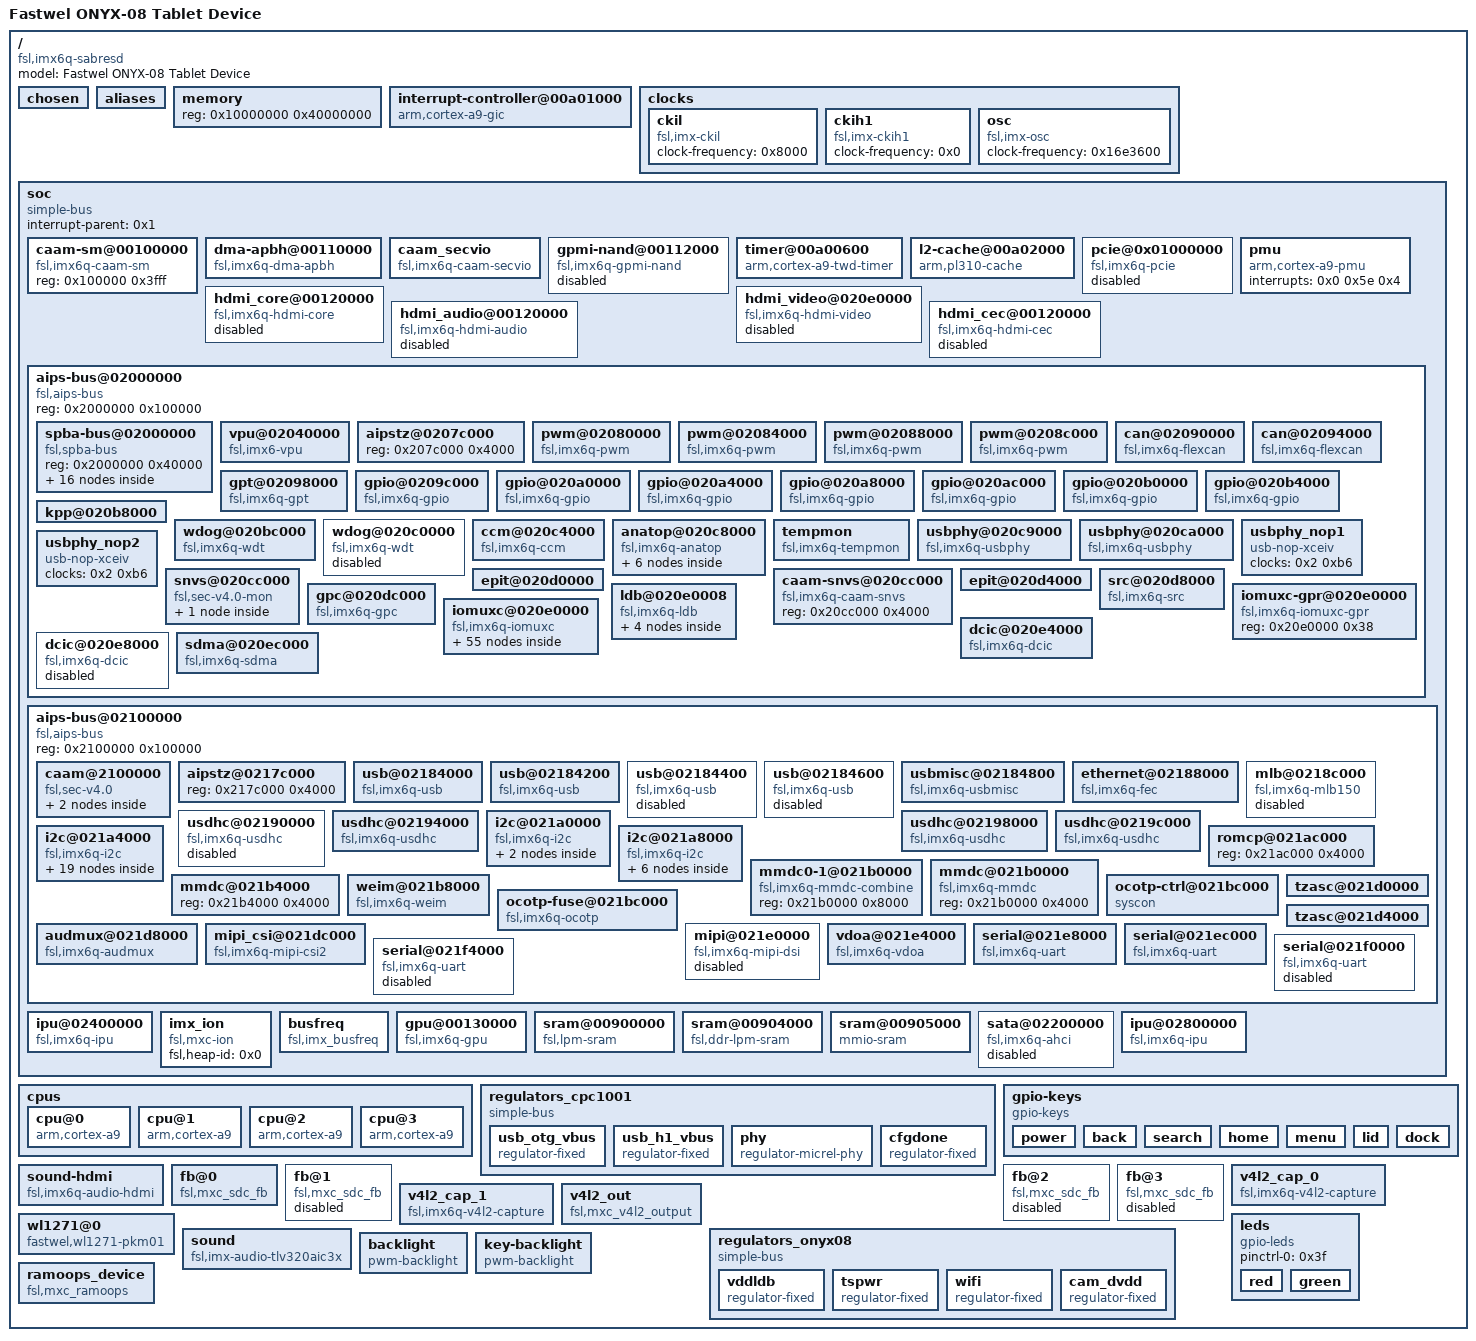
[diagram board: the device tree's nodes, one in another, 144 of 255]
/dts-v1/;

/ {
	#address-cells = <0x1>;
	#size-cells = <0x1>;
	model = "Fastwel ONYX-08 Tablet Device";
	compatible = "fsl,imx6q-sabresd", "fsl,imx6q", "fsl-onyx08";

	chosen {
	};

	aliases {
		gpio0 = "/soc/aips-bus@02000000/gpio@0209c000";
		gpio1 = "/soc/aips-bus@02000000/gpio@020a0000";
		gpio2 = "/soc/aips-bus@02000000/gpio@020a4000";
		gpio3 = "/soc/aips-bus@02000000/gpio@020a8000";
		gpio4 = "/soc/aips-bus@02000000/gpio@020ac000";
		gpio5 = "/soc/aips-bus@02000000/gpio@020b0000";
		gpio6 = "/soc/aips-bus@02000000/gpio@020b4000";
		i2c0 = "/soc/aips-bus@02100000/i2c@021a0000";
		i2c1 = "/soc/aips-bus@02100000/i2c@021a4000";
		i2c2 = "/soc/aips-bus@02100000/i2c@021a8000";
		ipu0 = "/soc/ipu@02400000";
		mmc0 = "/soc/aips-bus@02100000/usdhc@02190000";
		mmc1 = "/soc/aips-bus@02100000/usdhc@02194000";
		mmc2 = "/soc/aips-bus@02100000/usdhc@02198000";
		mmc3 = "/soc/aips-bus@02100000/usdhc@0219c000";
		serial0 = "/soc/aips-bus@02000000/spba-bus@02000000/serial@02020000";
		serial1 = "/soc/aips-bus@02100000/serial@021e8000";
		serial2 = "/soc/aips-bus@02100000/serial@021ec000";
		serial3 = "/soc/aips-bus@02100000/serial@021f0000";
		serial4 = "/soc/aips-bus@02100000/serial@021f4000";
		spi0 = "/soc/aips-bus@02000000/spba-bus@02000000/ecspi@02008000";
		spi1 = "/soc/aips-bus@02000000/spba-bus@02000000/ecspi@0200c000";
		spi2 = "/soc/aips-bus@02000000/spba-bus@02000000/ecspi@02010000";
		spi3 = "/soc/aips-bus@02000000/spba-bus@02000000/ecspi@02014000";
		usbphy0 = "/soc/aips-bus@02000000/usbphy@020c9000";
		usbphy1 = "/soc/aips-bus@02000000/usbphy@020ca000";
		ipu1 = "/soc/ipu@02800000";
		mxcfb0 = "/fb@0";
		mxcfb1 = "/fb@1";
		mxcfb2 = "/fb@2";
		mxcfb3 = "/fb@3";
	};

	memory {
		device_type = "memory";
		reg = <0x10000000 0x40000000>;
	};

	interrupt-controller@00a01000 {
		compatible = "arm,cortex-a9-gic";
		#interrupt-cells = <0x3>;
		#address-cells = <0x1>;
		#size-cells = <0x1>;
		interrupt-controller;
		reg = <0xa01000 0x1000 0xa00100 0x100>;
		linux,phandle = <0x1>;
		phandle = <0x1>;
	};

	clocks {
		#address-cells = <0x1>;
		#size-cells = <0x0>;

		ckil {
			compatible = "fsl,imx-ckil", "fixed-clock";
			clock-frequency = <0x8000>;
		};

		ckih1 {
			compatible = "fsl,imx-ckih1", "fixed-clock";
			clock-frequency = <0x0>;
		};

		osc {
			compatible = "fsl,imx-osc", "fixed-clock";
			clock-frequency = <0x16e3600>;
		};
	};

	soc {
		#address-cells = <0x1>;
		#size-cells = <0x1>;
		compatible = "simple-bus";
		interrupt-parent = <0x1>;
		ranges;

		caam-sm@00100000 {
			compatible = "fsl,imx6q-caam-sm";
			reg = <0x100000 0x3fff>;
		};

		dma-apbh@00110000 {
			compatible = "fsl,imx6q-dma-apbh", "fsl,imx28-dma-apbh";
			reg = <0x110000 0x2000>;
			interrupts = <0x0 0xd 0x4 0x0 0xd 0x4 0x0 0xd 0x4 0x0 0xd 0x4>;
			interrupt-names = "gpmi0", "gpmi1", "gpmi2", "gpmi3";
			#dma-cells = <0x1>;
			dma-channels = <0x4>;
			clocks = <0x2 0x6a>;
			linux,phandle = <0x3>;
			phandle = <0x3>;
		};

		caam_secvio {
			compatible = "fsl,imx6q-caam-secvio";
			interrupts = <0x0 0x14 0x4>;
			secvio_src = <0x8000001d>;
		};

		gpmi-nand@00112000 {
			compatible = "fsl,imx6q-gpmi-nand";
			#address-cells = <0x1>;
			#size-cells = <0x1>;
			reg = <0x112000 0x2000 0x114000 0x2000>;
			reg-names = "gpmi-nand", "bch";
			interrupts = <0x0 0xf 0x4>;
			interrupt-names = "bch";
			clocks = <0x2 0x98 0x2 0x99 0x2 0x97 0x2 0x96 0x2 0x95>;
			clock-names = "gpmi_io", "gpmi_apb", "gpmi_bch", "gpmi_bch_apb", "per1_bch";
			dmas = <0x3 0x0>;
			dma-names = "rx-tx";
			status = "disabled";
		};

		timer@00a00600 {
			compatible = "arm,cortex-a9-twd-timer";
			reg = <0xa00600 0x20>;
			interrupts = <0x1 0xd 0xf01>;
			clocks = <0x2 0xf>;
		};

		l2-cache@00a02000 {
			compatible = "arm,pl310-cache";
			reg = <0xa02000 0x1000>;
			interrupts = <0x0 0x5c 0x4>;
			cache-unified;
			cache-level = <0x2>;
			arm,tag-latency = <0x4 0x2 0x3>;
			arm,data-latency = <0x4 0x2 0x3>;
			linux,phandle = <0x36>;
			phandle = <0x36>;
		};

		pcie@0x01000000 {
			compatible = "fsl,imx6q-pcie", "snps,dw-pcie";
			reg = <0x1ffc000 0x4000 0x1f00000 0x80000>;
			reg-names = "dbi", "config";
			#address-cells = <0x3>;
			#size-cells = <0x2>;
			device_type = "pci";
			ranges = <0x81000000 0x0 0x0 0x1f80000 0x0 0x10000 0x82000000 0x0 0x1000000 0x1000000 0x0 0xf00000>;
			num-lanes = <0x1>;
			interrupts = <0x0 0x78 0x4>;
			interrupt-names = "msi";
			#interrupt-cells = <0x1>;
			interrupt-map-mask = <0x0 0x0 0x0 0x7>;
			interrupt-map = <0x0 0x0 0x0 0x1 0x1 0x0 0x7b 0x4 0x0 0x0 0x0 0x2 0x1 0x0 0x7a 0x4 0x0 0x0 0x0 0x3 0x1 0x0 0x79 0x4 0x0 0x0 0x0 0x4 0x1 0x0 0x78 0x4>;
			clocks = <0x2 0xbd 0x2 0xbb 0x2 0xce 0x2 0x90>;
			clock-names = "pcie_phy", "ref_100m", "pcie_bus", "pcie";
			status = "disabled";
			pinctrl-names = "default";
			pinctrl-0 = <0x4>;
			wake-up-gpio = <0x5 0xa 0x0>;
			reset-gpio = <0x6 0x13 0x0>;
		};

		pmu {
			compatible = "arm,cortex-a9-pmu";
			interrupts = <0x0 0x5e 0x4>;
		};

		hdmi_core@00120000 {
			compatible = "fsl,imx6q-hdmi-core";
			reg = <0x120000 0x9000>;
			clocks = <0x2 0x7c 0x2 0x7b 0x2 0x8a>;
			clock-names = "hdmi_isfr", "hdmi_iahb", "mipi_core";
			status = "disabled";
			ipu_id = <0x0>;
			disp_id = <0x1>;
		};

		hdmi_video@020e0000 {
			compatible = "fsl,imx6q-hdmi-video";
			reg = <0x20e0000 0x1000>;
			reg-names = "hdmi_gpr";
			interrupts = <0x0 0x73 0x4>;
			clocks = <0x2 0x7c 0x2 0x7b 0x2 0x8a>;
			clock-names = "hdmi_isfr", "hdmi_iahb", "mipi_core";
			status = "disabled";
			fsl,phy_reg_vlev = <0x294>;
			fsl,phy_reg_cksymtx = <0x800d>;
		};

		hdmi_audio@00120000 {
			compatible = "fsl,imx6q-hdmi-audio";
			clocks = <0x2 0x7c 0x2 0x7b 0x2 0x8a>;
			clock-names = "hdmi_isfr", "hdmi_iahb", "mipi_core";
			dmas = <0x7 0x2 0x18 0x0>;
			dma-names = "tx";
			status = "disabled";
			linux,phandle = <0x3d>;
			phandle = <0x3d>;
		};

		hdmi_cec@00120000 {
			compatible = "fsl,imx6q-hdmi-cec";
			interrupts = <0x0 0x73 0x4>;
			status = "disabled";
			pinctrl-names = "default";
			pinctrl-0 = <0x8>;
		};

		aips-bus@02000000 {
			compatible = "fsl,aips-bus", "simple-bus";
			#address-cells = <0x1>;
			#size-cells = <0x1>;
			reg = <0x2000000 0x100000>;
			ranges;

			spba-bus@02000000 {
				compatible = "fsl,spba-bus", "simple-bus";
				#address-cells = <0x1>;
				#size-cells = <0x1>;
				reg = <0x2000000 0x40000>;
				ranges;

				spdif@02004000 {
					compatible = "fsl,imx35-spdif";
					reg = <0x2004000 0x4000>;
					interrupts = <0x0 0x34 0x4>;
					dmas = <0x7 0xe 0x12 0x0 0x7 0xf 0x12 0x0>;
					dma-names = "rx", "tx";
					clocks = <0x2 0xf9 0x2 0x3 0x2 0xc5 0x2 0x6b 0x2 0x0 0x2 0x76 0x2 0x3e 0x2 0x8b 0x2 0x0 0x2 0x9c>;
					clock-names = "core", "rxtx0", "rxtx1", "rxtx2", "rxtx3", "rxtx4", "rxtx5", "rxtx6", "rxtx7", "dma";
					status = "disabled";
				};

				ecspi@02008000 {
					#address-cells = <0x1>;
					#size-cells = <0x0>;
					compatible = "fsl,imx6q-ecspi", "fsl,imx51-ecspi";
					reg = <0x2008000 0x4000>;
					interrupts = <0x0 0x1f 0x4>;
					clocks = <0x2 0x70 0x2 0x70>;
					clock-names = "ipg", "per";
					status = "okay";
					dmas = <0x7 0x3 0x7 0x1 0x7 0x4 0x7 0x2>;
					dma-names = "rx", "tx";
					fsl,spi-num-chipselects = <0x2>;
					cs-gpios = <0x6 0x1e 0x0 0x9 0x13 0x0>;
					pinctrl-names = "default";
					pinctrl-0 = <0xa>;

					at45db321d@0 {
						reg = <0x0>;
						#address-cells = <0x1>;
						#size-cells = <0x1>;
						compatible = "atmel,at45db321d", "atmel,at45", "atmel,dataflash";
						spi-max-frequency = <0x989680>;

						partition@0 {
							label = "U-Boot";
							reg = <0x0 0x40320>;
							read-only;
						};

						partition@40000 {
							label = "Kernel";
							reg = <0x40320 0x3dfce0>;
						};
					};
				};

				ecspi@0200c000 {
					#address-cells = <0x1>;
					#size-cells = <0x0>;
					compatible = "fsl,imx6q-ecspi", "fsl,imx51-ecspi";
					reg = <0x200c000 0x4000>;
					interrupts = <0x0 0x20 0x4>;
					clocks = <0x2 0x71 0x2 0x71>;
					clock-names = "ipg", "per";
					status = "disabled";
					dmas = <0x7 0x5 0x7 0x1 0x7 0x6 0x7 0x2>;
					dma-names = "rx", "tx";
					fsl,spi-num-chipselects = <0x2>;
					cs-gpios = <0x6 0x1a 0x0 0x6 0x1b 0x0>;
					pinctrl-names = "default";
					pinctrl-0 = <0xb>;
				};

				ecspi@02010000 {
					#address-cells = <0x1>;
					#size-cells = <0x0>;
					compatible = "fsl,imx6q-ecspi", "fsl,imx51-ecspi";
					reg = <0x2010000 0x4000>;
					interrupts = <0x0 0x21 0x4>;
					clocks = <0x2 0x72 0x2 0x72>;
					clock-names = "ipg", "per";
					status = "disabled";
					dmas = <0x7 0x7 0x7 0x1 0x7 0x8 0x7 0x2>;
					dma-names = "rx", "tx";
				};

				ecspi@02014000 {
					#address-cells = <0x1>;
					#size-cells = <0x0>;
					compatible = "fsl,imx6q-ecspi", "fsl,imx51-ecspi";
					reg = <0x2014000 0x4000>;
					interrupts = <0x0 0x22 0x4>;
					clocks = <0x2 0x73 0x2 0x73>;
					clock-names = "ipg", "per";
					status = "disabled";
					dmas = <0x7 0x9 0x7 0x1 0x7 0xa 0x7 0x2>;
					dma-names = "rx", "tx";
				};

				serial@02020000 {
					compatible = "fsl,imx6q-uart", "fsl,imx21-uart";
					reg = <0x2020000 0x4000>;
					interrupts = <0x0 0x1a 0x4>;
					clocks = <0x2 0xa0 0x2 0xa1>;
					clock-names = "ipg", "per";
					dmas = <0x7 0x19 0x4 0x0 0x7 0x1a 0x4 0x0>;
					dma-names = <0x747800>;
					status = "okay";
					pinctrl-names = "default";
					pinctrl-0 = <0xc>;
				};

				esai@02024000 {
					compatible = "fsl,imx35-esai";
					reg = <0x2024000 0x4000>;
					interrupts = <0x0 0x33 0x4>;
					clocks = <0x2 0xd9 0x2 0xd0 0x2 0x76 0x2 0xd9 0x2 0x9c>;
					clock-names = "core", "mem", "extal", "fsys", "dma";
					dmas = <0x7 0x17 0x15 0x0 0x7 0x18 0x15 0x0>;
					dma-names = "rx", "tx";
					status = "disabled";
				};

				ssi@02028000 {
					compatible = "fsl,imx6q-ssi", "fsl,imx21-ssi";
					reg = <0x2028000 0x4000>;
					interrupts = <0x0 0x2e 0x4>;
					clocks = <0x2 0xb2 0x2 0x9d>;
					clock-names = "ipg", "baud";
					dmas = <0x7 0x25 0x16 0x0 0x7 0x26 0x16 0x0>;
					dma-names = "rx", "tx";
					fsl,fifo-depth = <0xf>;
					fsl,ssi-dma-events = <0x26 0x25>;
					status = "disabled";
				};

				ssi@0202c000 {
					compatible = "fsl,imx6q-ssi", "fsl,imx21-ssi";
					reg = <0x202c000 0x4000>;
					interrupts = <0x0 0x2f 0x4>;
					clocks = <0x2 0xb3 0x2 0x9e>;
					clock-names = "ipg", "baud";
					dmas = <0x7 0x29 0x16 0x0 0x7 0x2a 0x16 0x0>;
					dma-names = "rx", "tx";
					fsl,fifo-depth = <0xf>;
					fsl,ssi-dma-events = <0x2a 0x29>;
					status = "okay";
					fsl,mode = "i2s-slave";
					linux,phandle = <0x40>;
					phandle = <0x40>;
				};

				ssi@02030000 {
					compatible = "fsl,imx6q-ssi", "fsl,imx21-ssi";
					reg = <0x2030000 0x4000>;
					interrupts = <0x0 0x30 0x4>;
					clocks = <0x2 0xb4 0x2 0x9f>;
					clock-names = "ipg", "baud";
					dmas = <0x7 0x2d 0x16 0x0 0x7 0x2e 0x16 0x0>;
					dma-names = "rx", "tx";
					fsl,fifo-depth = <0xf>;
					fsl,ssi-dma-events = <0x2e 0x2d>;
					status = "disabled";
				};

				asrc@02034000 {
					compatible = "fsl,imx53-asrc";
					reg = <0x2034000 0x4000>;
					interrupts = <0x0 0x32 0x4>;
					clocks = <0x2 0xda 0x2 0xdb 0x2 0x0 0x2 0x0 0x2 0x0 0x2 0x0 0x2 0x0 0x2 0x0 0x2 0x0 0x2 0x0 0x2 0x0 0x2 0x0 0x2 0x0 0x2 0x0 0x2 0x0 0x2 0x6b 0x2 0x0 0x2 0x0 0x2 0x9c>;
					clock-names = "mem", "ipg", "asrck_0", "asrck_1", "asrck_2", "asrck_3", "asrck_4", "asrck_5", "asrck_6", "asrck_7", "asrck_8", "asrck_9", "asrck_a", "asrck_b", "asrck_c", "asrck_d", "asrck_e", "asrck_f", "dma";
					dmas = <0x7 0x11 0x17 0x1 0x7 0x12 0x17 0x1 0x7 0x13 0x17 0x1 0x7 0x14 0x17 0x1 0x7 0x15 0x17 0x1 0x7 0x16 0x17 0x1>;
					dma-names = "rxa", "rxb", "rxc", "txa", "txb", "txc";
					fsl,asrc-rate = <0xbb80>;
					fsl,asrc-width = <0x10>;
					status = "okay";
				};

				spba@0203c000 {
					reg = <0x203c000 0x4000>;
				};

				ecspi@02018000 {
					#address-cells = <0x1>;
					#size-cells = <0x0>;
					compatible = "fsl,imx6q-ecspi", "fsl,imx51-ecspi";
					reg = <0x2018000 0x4000>;
					interrupts = <0x0 0x23 0x4>;
					clocks = <0x2 0x74 0x2 0x74>;
					clock-names = "ipg", "per";
					status = "disabled";
				};
			};

			vpu@02040000 {
				compatible = "fsl,imx6-vpu";
				reg = <0x2040000 0x3c000>;
				reg-names = "vpu_regs";
				interrupts = <0x0 0x3 0x1 0x0 0xc 0x4>;
				interrupt-names = "vpu_jpu_irq", "vpu_ipi_irq";
				clocks = <0x2 0xa8 0x2 0x8c 0x2 0x8e>;
				clock-names = "vpu_clk", "mmdc_ch0_axi", "ocram";
				iramsize = <0x21000>;
				iram = <0xd>;
				resets = <0xe 0x1>;
				power-domains = <0xf 0x1>;
				pu-supply = <0x10>;
			};

			aipstz@0207c000 {
				reg = <0x207c000 0x4000>;
			};

			pwm@02080000 {
				#pwm-cells = <0x2>;
				compatible = "fsl,imx6q-pwm", "fsl,imx27-pwm";
				reg = <0x2080000 0x4000>;
				interrupts = <0x0 0x53 0x4>;
				clocks = <0x2 0x3e 0x2 0x91>;
				clock-names = "ipg", "per";
				pinctrl-names = "default";
				pinctrl-0 = <0x11>;
				status = "okay";
				linux,phandle = <0x42>;
				phandle = <0x42>;
			};

			pwm@02084000 {
				#pwm-cells = <0x2>;
				compatible = "fsl,imx6q-pwm", "fsl,imx27-pwm";
				reg = <0x2084000 0x4000>;
				interrupts = <0x0 0x54 0x4>;
				clocks = <0x2 0x3e 0x2 0x92>;
				clock-names = "ipg", "per";
				pinctrl-names = "default";
				pinctrl-0 = <0x12>;
				status = "okay";
				linux,phandle = <0x43>;
				phandle = <0x43>;
			};

			pwm@02088000 {
				#pwm-cells = <0x2>;
				compatible = "fsl,imx6q-pwm", "fsl,imx27-pwm";
				reg = <0x2088000 0x4000>;
				interrupts = <0x0 0x55 0x4>;
				clocks = <0x2 0x3e 0x2 0x93>;
				clock-names = "ipg", "per";
			};

			pwm@0208c000 {
				#pwm-cells = <0x2>;
				compatible = "fsl,imx6q-pwm", "fsl,imx27-pwm";
				reg = <0x208c000 0x4000>;
				interrupts = <0x0 0x56 0x4>;
				clocks = <0x2 0x3e 0x2 0x94>;
				clock-names = "ipg", "per";
			};

			can@02090000 {
				compatible = "fsl,imx6q-flexcan";
				reg = <0x2090000 0x4000>;
				interrupts = <0x0 0x6e 0x4>;
				clocks = <0x2 0x6c 0x2 0x6d>;
				clock-names = "ipg", "per";
				stop-mode = <0x13 0x34 0x1c 0x10 0x11>;
				status = "okay";
				pinctrl-names = "default";
				pinctrl-0 = <0x14>;
				trx-nerr-gpio = <0x6 0x4 0x0>;
			};

			can@02094000 {
				compatible = "fsl,imx6q-flexcan";
				reg = <0x2094000 0x4000>;
				interrupts = <0x0 0x6f 0x4>;
				clocks = <0x2 0x6e 0x2 0x6f>;
				clock-names = "ipg", "per";
				stop-mode = <0x13 0x34 0x1d 0x10 0x12>;
				status = "okay";
				pinctrl-names = "default";
				pinctrl-0 = <0x15>;
				trx-nerr-gpio = <0x6 0x5 0x0>;
			};

			gpt@02098000 {
				compatible = "fsl,imx6q-gpt", "fsl,imx31-gpt";
				reg = <0x2098000 0x4000>;
				interrupts = <0x0 0x37 0x4>;
				clocks = <0x2 0x77 0x2 0x78>;
				clock-names = "ipg", "per";
			};

			gpio@0209c000 {
				compatible = "fsl,imx6q-gpio", "fsl,imx35-gpio";
				reg = <0x209c000 0x4000>;
				interrupts = <0x0 0x42 0x4 0x0 0x43 0x4>;
				gpio-controller;
				#gpio-cells = <0x2>;
				interrupt-controller;
				#interrupt-cells = <0x2>;
				linux,phandle = <0x28>;
				phandle = <0x28>;
			};

			gpio@020a0000 {
				compatible = "fsl,imx6q-gpio", "fsl,imx35-gpio";
				reg = <0x20a0000 0x4000>;
				interrupts = <0x0 0x44 0x4 0x0 0x45 0x4>;
				gpio-controller;
				#gpio-cells = <0x2>;
				interrupt-controller;
				#interrupt-cells = <0x2>;
				linux,phandle = <0x6>;
				phandle = <0x6>;
			};

			gpio@020a4000 {
				compatible = "fsl,imx6q-gpio", "fsl,imx35-gpio";
				reg = <0x20a4000 0x4000>;
				interrupts = <0x0 0x46 0x4 0x0 0x47 0x4>;
				gpio-controller;
				#gpio-cells = <0x2>;
				interrupt-controller;
				#interrupt-cells = <0x2>;
				linux,phandle = <0x9>;
				phandle = <0x9>;
			};

			gpio@020a8000 {
				compatible = "fsl,imx6q-gpio", "fsl,imx35-gpio";
				reg = <0x20a8000 0x4000>;
				interrupts = <0x0 0x48 0x4 0x0 0x49 0x4>;
				gpio-controller;
				#gpio-cells = <0x2>;
				interrupt-controller;
				#interrupt-cells = <0x2>;
				linux,phandle = <0x5>;
				phandle = <0x5>;
			};

			gpio@020ac000 {
				compatible = "fsl,imx6q-gpio", "fsl,imx35-gpio";
				reg = <0x20ac000 0x4000>;
				interrupts = <0x0 0x4a 0x4 0x0 0x4b 0x4>;
				gpio-controller;
				#gpio-cells = <0x2>;
				interrupt-controller;
				#interrupt-cells = <0x2>;
				linux,phandle = <0x3c>;
				phandle = <0x3c>;
			};

			gpio@020b0000 {
				compatible = "fsl,imx6q-gpio", "fsl,imx35-gpio";
				reg = <0x20b0000 0x4000>;
				interrupts = <0x0 0x4c 0x4 0x0 0x4d 0x4>;
				gpio-controller;
				#gpio-cells = <0x2>;
				interrupt-controller;
				#interrupt-cells = <0x2>;
				linux,phandle = <0x2d>;
				phandle = <0x2d>;
			};

			gpio@020b4000 {
				compatible = "fsl,imx6q-gpio", "fsl,imx35-gpio";
				reg = <0x20b4000 0x4000>;
				interrupts = <0x0 0x4e 0x4 0x0 0x4f 0x4>;
				gpio-controller;
				#gpio-cells = <0x2>;
				interrupt-controller;
				#interrupt-cells = <0x2>;
				linux,phandle = <0x32>;
				phandle = <0x32>;
			};

			kpp@020b8000 {
				reg = <0x20b8000 0x4000>;
				interrupts = <0x0 0x52 0x4>;
			};

			wdog@020bc000 {
				compatible = "fsl,imx6q-wdt", "fsl,imx21-wdt";
				reg = <0x20bc000 0x4000>;
				interrupts = <0x0 0x50 0x4>;
				clocks = <0x2 0x0>;
				status = "okay";
			};

			wdog@020c0000 {
				compatible = "fsl,imx6q-wdt", "fsl,imx21-wdt";
				reg = <0x20c0000 0x4000>;
				interrupts = <0x0 0x51 0x4>;
				clocks = <0x2 0x0>;
				status = "disabled";
			};

			ccm@020c4000 {
				compatible = "fsl,imx6q-ccm";
				reg = <0x20c4000 0x4000>;
				interrupts = <0x0 0x57 0x4 0x0 0x58 0x4>;
				#clock-cells = <0x1>;
				linux,phandle = <0x2>;
				phandle = <0x2>;
			};

			anatop@020c8000 {
				compatible = "fsl,imx6q-anatop", "syscon", "simple-bus";
				reg = <0x20c8000 0x1000>;
				interrupts = <0x0 0x31 0x4 0x0 0x36 0x4 0x0 0x7f 0x4>;
				linux,phandle = <0x16>;
				phandle = <0x16>;

				regulator-1p1@110 {
					compatible = "fsl,anatop-regulator";
					regulator-name = "vdd1p1";
					regulator-min-microvolt = <0xc3500>;
					regulator-max-microvolt = <0x14fb18>;
					regulator-always-on;
					anatop-reg-offset = <0x110>;
					anatop-vol-bit-shift = <0x8>;
					anatop-vol-bit-width = <0x5>;
					anatop-min-bit-val = <0x4>;
					anatop-min-voltage = <0xc3500>;
					anatop-max-voltage = <0x14fb18>;
					anatop-enable-bit = <0x0>;
				};

				regulator-3p0@120 {
					compatible = "fsl,anatop-regulator";
					regulator-name = "vdd3p0";
					regulator-min-microvolt = <0x280de8>;
					regulator-max-microvolt = <0x33e140>;
					anatop-reg-offset = <0x120>;
					anatop-vol-bit-shift = <0x8>;
					anatop-vol-bit-width = <0x5>;
					anatop-min-bit-val = <0x0>;
					anatop-min-voltage = <0x280de8>;
					anatop-max-voltage = <0x33e140>;
					anatop-enable-bit = <0x0>;
					linux,phandle = <0x18>;
					phandle = <0x18>;
				};

				regulator-2p5@130 {
					compatible = "fsl,anatop-regulator";
					regulator-name = "vdd2p5";
					regulator-min-microvolt = <0x1e8480>;
					regulator-max-microvolt = <0x29f630>;
					regulator-always-on;
					anatop-reg-offset = <0x130>;
					anatop-vol-bit-shift = <0x8>;
					anatop-vol-bit-width = <0x5>;
					anatop-min-bit-val = <0x0>;
					anatop-min-voltage = <0x1e8480>;
					anatop-max-voltage = <0x29f630>;
					anatop-enable-bit = <0x0>;
				};

				regulator-vddcore@140 {
					compatible = "fsl,anatop-regulator";
					regulator-name = "vddarm";
					regulator-min-microvolt = <0xb1008>;
					regulator-max-microvolt = <0x162010>;
					regulator-always-on;
					anatop-reg-offset = <0x140>;
					anatop-vol-bit-shift = <0x0>;
					anatop-vol-bit-width = <0x5>;
					anatop-delay-reg-offset = <0x170>;
					anatop-delay-bit-shift = <0x18>;
					anatop-delay-bit-width = <0x2>;
					anatop-min-bit-val = <0x1>;
					anatop-min-voltage = <0xb1008>;
					anatop-max-voltage = <0x162010>;
					regulator-allow-bypass;
					linux,phandle = <0x37>;
					phandle = <0x37>;
				};

				regulator-vddpu@140 {
					compatible = "fsl,anatop-regulator";
					regulator-name = "vddpu";
					regulator-min-microvolt = <0xb1008>;
					regulator-max-microvolt = <0x162010>;
					regulator-enable-ramp-delay = <0x96>;
					regulator-boot-on;
					anatop-reg-offset = <0x140>;
					anatop-vol-bit-shift = <0x9>;
					anatop-vol-bit-width = <0x5>;
					anatop-delay-reg-offset = <0x170>;
					anatop-delay-bit-shift = <0x1a>;
					anatop-delay-bit-width = <0x2>;
					anatop-min-bit-val = <0x1>;
					anatop-min-voltage = <0xb1008>;
					anatop-max-voltage = <0x162010>;
					regulator-allow-bypass;
					linux,phandle = <0x10>;
					phandle = <0x10>;
				};

				regulator-vddsoc@140 {
					compatible = "fsl,anatop-regulator";
					regulator-name = "vddsoc";
					regulator-min-microvolt = <0xb1008>;
					regulator-max-microvolt = <0x162010>;
					regulator-always-on;
					anatop-reg-offset = <0x140>;
					anatop-vol-bit-shift = <0x12>;
					anatop-vol-bit-width = <0x5>;
					anatop-delay-reg-offset = <0x170>;
					anatop-delay-bit-shift = <0x1c>;
					anatop-delay-bit-width = <0x2>;
					anatop-min-bit-val = <0x1>;
					anatop-min-voltage = <0xb1008>;
					anatop-max-voltage = <0x162010>;
					regulator-allow-bypass;
					linux,phandle = <0x38>;
					phandle = <0x38>;
				};
			};

			tempmon {
				compatible = "fsl,imx6q-tempmon";
				interrupts = <0x0 0x31 0x4>;
				fsl,tempmon = <0x16>;
				fsl,tempmon-data = <0x17>;
				clocks = <0x2 0xac>;
			};

			usbphy@020c9000 {
				compatible = "fsl,imx6q-usbphy", "fsl,imx23-usbphy";
				reg = <0x20c9000 0x1000>;
				interrupts = <0x0 0x2c 0x4>;
				clocks = <0x2 0xb6>;
				phy-3p0-supply = <0x18>;
				fsl,anatop = <0x16>;
				linux,phandle = <0x1c>;
				phandle = <0x1c>;
			};

			usbphy@020ca000 {
				compatible = "fsl,imx6q-usbphy", "fsl,imx23-usbphy";
				reg = <0x20ca000 0x1000>;
				interrupts = <0x0 0x2d 0x4>;
				clocks = <0x2 0xb7>;
				phy-3p0-supply = <0x18>;
				fsl,anatop = <0x16>;
				linux,phandle = <0x20>;
				phandle = <0x20>;
			};

			usbphy_nop1 {
				compatible = "usb-nop-xceiv";
				clocks = <0x2 0xb6>;
				clock-names = "main_clk";
				linux,phandle = <0x22>;
				phandle = <0x22>;
			};

			usbphy_nop2 {
				compatible = "usb-nop-xceiv";
				clocks = <0x2 0xb6>;
				clock-names = "main_clk";
				linux,phandle = <0x23>;
				phandle = <0x23>;
			};

			caam-snvs@020cc000 {
				compatible = "fsl,imx6q-caam-snvs";
				reg = <0x20cc000 0x4000>;
			};

			snvs@020cc000 {
				compatible = "fsl,sec-v4.0-mon", "simple-bus";
				#address-cells = <0x1>;
				#size-cells = <0x1>;
				ranges = <0x0 0x20cc000 0x4000>;

				snvs-rtc-lp@34 {
					compatible = "fsl,sec-v4.0-mon-rtc-lp";
					reg = <0x34 0x58>;
					interrupts = <0x0 0x13 0x4 0x0 0x14 0x4>;
				};
			};

			epit@020d0000 {
				reg = <0x20d0000 0x4000>;
				interrupts = <0x0 0x38 0x4>;
			};

			epit@020d4000 {
				reg = <0x20d4000 0x4000>;
				interrupts = <0x0 0x39 0x4>;
			};

			src@020d8000 {
				compatible = "fsl,imx6q-src", "fsl,imx51-src";
				reg = <0x20d8000 0x4000>;
				interrupts = <0x0 0x5b 0x4 0x0 0x60 0x4>;
				#reset-cells = <0x1>;
				linux,phandle = <0xe>;
				phandle = <0xe>;
			};

			gpc@020dc000 {
				compatible = "fsl,imx6q-gpc";
				reg = <0x20dc000 0x4000>;
				interrupts = <0x0 0x59 0x4 0x0 0x5a 0x4>;
				pu-supply = <0x10>;
				clocks = <0x2 0x7a 0x2 0x4a 0x2 0x79 0x2 0x1a 0x2 0x8f 0x2 0xa8 0x2 0x3e>;
				#power-domain-cells = <0x1>;
				fsl,cpu_pupscr_sw2iso = <0xf>;
				fsl,cpu_pupscr_sw = <0xf>;
				fsl,cpu_pdnscr_iso2sw = <0x1>;
				fsl,cpu_pdnscr_iso = <0x1>;
				fsl,ldo-bypass = <0x0>;
				fsl,wdog-reset = <0x1>;
				linux,phandle = <0xf>;
				phandle = <0xf>;
			};

			iomuxc-gpr@020e0000 {
				compatible = "fsl,imx6q-iomuxc-gpr", "syscon";
				reg = <0x20e0000 0x38>;
				linux,phandle = <0x13>;
				phandle = <0x13>;
			};

			iomuxc@020e0000 {
				compatible = "fsl,imx6q-iomuxc";
				reg = <0x20e0000 0x4000>;
				pinctrl-names = "default";
				pinctrl-0 = <0x19>;

				ipu2 {

					ipu2grp-1 {
						fsl,pins = <0x15c 0x470 0x0 0x1 0x0 0x10 0x160 0x474 0x0 0x1 0x0 0x10 0x164 0x478 0x0 0x1 0x0 0x10 0x168 0x47c 0x0 0x1 0x0 0x10 0x16c 0x480 0x0 0x1 0x0 0x80000000 0x170 0x484 0x0 0x1 0x0 0x10 0x174 0x488 0x0 0x1 0x0 0x10 0x178 0x48c 0x0 0x1 0x0 0x10 0x17c 0x490 0x0 0x1 0x0 0x10 0x180 0x494 0x0 0x1 0x0 0x10 0x184 0x498 0x0 0x1 0x0 0x10 0x188 0x49c 0x0 0x1 0x0 0x10 0x18c 0x4a0 0x0 0x1 0x0 0x10 0x190 0x4a4 0x0 0x1 0x0 0x10 0x194 0x4a8 0x0 0x1 0x0 0x10 0x198 0x4ac 0x0 0x1 0x0 0x10 0x19c 0x4b0 0x0 0x1 0x0 0x10 0x1a0 0x4b4 0x0 0x1 0x0 0x10 0x1a4 0x4b8 0x0 0x1 0x0 0x10 0x1a8 0x4bc 0x0 0x1 0x0 0x10 0x1ac 0x4c0 0x0 0x1 0x0 0x10 0x1b0 0x4c4 0x0 0x1 0x0 0x10 0x1b4 0x4c8 0x0 0x1 0x0 0x10 0x1b8 0x4cc 0x0 0x1 0x0 0x10 0x1bc 0x4d0 0x0 0x1 0x0 0x10 0x1c0 0x4d4 0x0 0x1 0x0 0x10 0x1c4 0x4d8 0x0 0x1 0x0 0x10 0x1c8 0x4dc 0x0 0x1 0x0 0x10 0x1cc 0x4e0 0x0 0x1 0x0 0x10>;
					};
				};

				pkmfec {

					pkmfec-1 {
						fsl,pins = <0x1d0 0x4e4 0x840 0x1 0x0 0x1b0b0 0x1f4 0x508 0x0 0x1 0x0 0x1b0b0 0x58 0x36c 0x0 0x1 0x0 0x1b0b0 0x5c 0x370 0x0 0x1 0x0 0x1b030 0x60 0x374 0x0 0x1 0x0 0x1b030 0x64 0x378 0x0 0x1 0x0 0x1b030 0x68 0x37c 0x0 0x1 0x0 0x1b030 0x74 0x388 0x0 0x1 0x0 0x1b0b0 0x1d4 0x4e8 0x0 0x1 0x0 0x1b0b0 0x84 0x398 0x844 0x1 0x0 0x1b0b0 0x6c 0x380 0x858 0x1 0x0 0x1b0b0>;
						linux,phandle = <0x24>;
						phandle = <0x24>;
					};

					pkmfec-1-sleep {
						fsl,pins = <0x1d0 0x4e4 0x840 0x1 0x0 0x1b0b0 0x1f4 0x508 0x0 0x1 0x0 0x1b0b0 0x58 0x36c 0x0 0x1 0x0 0x1b0b0 0x5c 0x370 0x0 0x1 0x0 0x1b030 0x60 0x374 0x0 0x1 0x0 0x1b030 0x64 0x378 0x0 0x1 0x0 0x1b030 0x68 0x37c 0x0 0x1 0x0 0x1b030 0x74 0x388 0x0 0x1 0x0 0x1b0b0 0x1d4 0x4e8 0x0 0x1 0x0 0x1b0b0 0x84 0x398 0x844 0x1 0x0 0x1b0b0 0x6c 0x380 0x858 0x1 0x0 0x1b0b0>;
						linux,phandle = <0x25>;
						phandle = <0x25>;
					};
				};

				reg_phy {

					phy_on {
						fsl,pins = <0x70 0x384 0x848 0x1 0x0 0x1b030 0x78 0x38c 0x84c 0x1 0x0 0x1b030 0x7c 0x390 0x850 0x1 0x0 0x1b030 0x80 0x394 0x854 0x1 0x0 0x1b030>;
						linux,phandle = <0x3a>;
						phandle = <0x3a>;
					};

					phy_off {
						fsl,pins = <0x70 0x384 0x0 0x5 0x0 0x1b030 0x78 0x38c 0x0 0x5 0x0 0x1b030 0x7c 0x390 0x0 0x5 0x0 0x1b030 0x80 0x394 0x0 0x5 0x0 0x1b030>;
						linux,phandle = <0x3b>;
						phandle = <0x3b>;
					};
				};

				uart1 {

					uart1grp-1 {
						fsl,pins = <0x280 0x650 0x0 0x3 0x0 0x1b0b1 0x284 0x654 0x920 0x3 0x1 0x1b0b1>;
						linux,phandle = <0xc>;
						phandle = <0xc>;
					};
				};

				uart2 {

					uart2grp-1 {
						fsl,pins = <0xbc 0x3d0 0x0 0x4 0x0 0x1b0b1 0xc0 0x3d4 0x928 0x4 0x1 0x1b0b1>;
					};

					uart2grp-3 {
						fsl,pins = <0xbc 0x3d0 0x0 0x4 0x0 0x1b0b1 0xc0 0x3d4 0x928 0x4 0x1 0x1b0b1 0xc4 0x3d8 0x0 0x4 0x0 0x1b0b1 0xc8 0x3dc 0x924 0x4 0x1 0x1b0b1>;
						linux,phandle = <0x34>;
						phandle = <0x34>;
					};
				};

				uart3 {

					uart3grp-1 {
						fsl,pins = <0xb4 0x3c8 0x0 0x2 0x0 0x1b0b1 0xb8 0x3cc 0x930 0x2 0x1 0x1b0b1>;
						linux,phandle = <0x35>;
						phandle = <0x35>;
					};
				};

				pwm1 {

					pwm1grp-1 {
						fsl,pins = <0x344 0x72c 0x0 0x3 0x0 0x1b0b1>;
						linux,phandle = <0x11>;
						phandle = <0x11>;
					};
				};

				pwm2 {

					pwm2grp-1 {
						fsl,pins = <0x34c 0x734 0x0 0x3 0x0 0x1b0b1>;
						linux,phandle = <0x12>;
						phandle = <0x12>;
					};
				};

				usbotg {

					usbotggrp-1 {
						fsl,pins = <0x224 0x5f4 0x4 0x3 0xff0d0101 0x17059>;
						linux,phandle = <0x1f>;
						phandle = <0x1f>;
					};
				};

				hdmi_cec {

					hdmicecgrp-2 {
						fsl,pins = <0x20c 0x5dc 0x88c 0x6 0x1 0x1f8b0>;
						linux,phandle = <0x8>;
						phandle = <0x8>;
					};
				};

				flexcan1 {

					flexcan1grp-2 {
						fsl,pins = <0x240 0x610 0x0 0x3 0x0 0x80000000 0x20c 0x5dc 0x7e4 0x2 0x0 0x80000000>;
					};
				};

				flexcan2 {

					flexcan2grp-1 {
						fsl,pins = <0x218 0x5e8 0x0 0x0 0x0 0x80000000 0x21c 0x5ec 0x7e8 0x0 0x0 0x80000000>;
						linux,phandle = <0x15>;
						phandle = <0x15>;
					};
				};

				i2c1 {

					i2c1grp-2 {
						fsl,pins = <0x278 0x648 0x89c 0x4 0x1 0x4001b8b1 0x27c 0x64c 0x898 0x4 0x1 0x4001b8b1>;
						linux,phandle = <0x2b>;
						phandle = <0x2b>;
					};
				};

				i2c2 {

					i2c2grp-2 {
						fsl,pins = <0x210 0x5e0 0x8a0 0x4 0x1 0x4001b8b1 0x214 0x5e4 0x8a4 0x4 0x1 0x4001b8b1>;
						linux,phandle = <0x2e>;
						phandle = <0x2e>;
					};
				};

				i2c3 {

					i2c3grp-2 {
						fsl,pins = <0x22c 0x5fc 0x8a8 0x2 0x1 0x4001b8b1 0x230 0x600 0x8ac 0x2 0x1 0x4001b8b1>;
						linux,phandle = <0x31>;
						phandle = <0x31>;
					};
				};

				usdhc2 {

					usdhc2grp-2-50MHz-40Ohm {
						fsl,pins = <0x358 0x740 0x0 0x0 0x0 0x17071 0x354 0x73c 0x0 0x0 0x0 0x10071 0x54 0x368 0x0 0x0 0x0 0x17071 0x4c 0x360 0x0 0x0 0x0 0x17071 0x50 0x364 0x0 0x0 0x0 0x17071 0x35c 0x744 0x0 0x0 0x0 0x17071>;
						linux,phandle = <0x27>;
						phandle = <0x27>;
					};
				};

				usdhc3 {

					usdhc3grp-2 {
						fsl,pins = <0x2b8 0x6a0 0x0 0x0 0x0 0x17059 0x2bc 0x6a4 0x0 0x0 0x0 0x10059 0x2c0 0x6a8 0x0 0x0 0x0 0x17059 0x2c4 0x6ac 0x0 0x0 0x0 0x17059 0x2c8 0x6b0 0x0 0x0 0x0 0x17059 0x2cc 0x6b4 0x0 0x0 0x0 0x17059>;
						linux,phandle = <0x29>;
						phandle = <0x29>;
					};
				};

				usdhc4 {

					usdhc4grp-1 {
						fsl,pins = <0x2d8 0x6c0 0x0 0x1 0x0 0x1b0b0 0x2f4 0x6dc 0x0 0x0 0x0 0x17059 0x2f8 0x6e0 0x0 0x0 0x0 0x10059 0x31c 0x704 0x0 0x1 0x0 0x17059 0x320 0x708 0x0 0x1 0x0 0x17059 0x324 0x70c 0x0 0x1 0x0 0x17059 0x328 0x710 0x0 0x1 0x0 0x17059 0x32c 0x714 0x0 0x1 0x0 0x17059 0x330 0x718 0x0 0x1 0x0 0x17059 0x334 0x71c 0x0 0x1 0x0 0x17059 0x338 0x720 0x0 0x1 0x0 0x17059>;
						linux,phandle = <0x2a>;
						phandle = <0x2a>;
					};
				};

				ecspi1 {

					ecspi1grp-1 {
						fsl,pins = <0x94 0x3a8 0x7f8 0x1 0x0 0x100b1 0x98 0x3ac 0x7fc 0x1 0x0 0x100b1 0x90 0x3a4 0x7f4 0x1 0x0 0x100b1>;
						linux,phandle = <0xa>;
						phandle = <0xa>;
					};
				};

				ecspi2 {

					ecspi2grp-1 {
						fsl,pins = <0xf8 0x40c 0x810 0x2 0x0 0x100b1 0xfc 0x410 0x818 0x2 0x0 0x100b1 0x100 0x414 0x814 0x2 0x0 0x100b1>;
						linux,phandle = <0xb>;
						phandle = <0xb>;
					};
				};

				onyx08_can1 {

					flexcan1grp-3 {
						fsl,pins = <0x240 0x610 0x0 0x3 0x0 0x1b0b0 0x244 0x614 0x7e4 0x3 0x1 0x1b0b0>;
						linux,phandle = <0x14>;
						phandle = <0x14>;
					};
				};

				pcie {

					pcie_grp {
						fsl,pins = <0xe8 0x3fc 0x0 0x5 0x0 0x1b0b0 0x208 0x5d8 0x0 0x5 0x0 0x1b0b0>;
						linux,phandle = <0x4>;
						phandle = <0x4>;
					};
				};

				leds {

					gpio_leds {
						fsl,pins = <0x1c4 0x4d8 0x0 0x5 0x0 0x1b0b1 0x1a8 0x4bc 0x0 0x5 0x0 0x1b0b1>;
						linux,phandle = <0x3f>;
						phandle = <0x3f>;
					};
				};

				audmux {

					audmux-2 {
						fsl,pins = <0x274 0x644 0x0 0x4 0x0 0x130b0 0x268 0x638 0x0 0x4 0x0 0x130b0 0x26c 0x63c 0x0 0x4 0x0 0x110b0 0x270 0x640 0x0 0x4 0x0 0x130b0>;
						linux,phandle = <0x33>;
						phandle = <0x33>;
					};
				};

				battery {

					bq40z60-pins {
						fsl,pins = <0x2d4 0x6bc 0x0 0x5 0x0 0x1f0b0 0x2ec 0x6d4 0x0 0x5 0x0 0x1f0b0 0x2f0 0x6d8 0x0 0x5 0x0 0x110b0>;
						linux,phandle = <0x2c>;
						phandle = <0x2c>;
					};
				};

				hog {

					hoggrp-1 {
						fsl,pins = <0x238 0x608 0x0 0x6 0x0 0x80000000 0x254 0x624 0x0 0x3 0x0 0x130b0 0x170 0x484 0x0 0x5 0x0 0x1f0b0 0xa0 0x3b4 0x0 0x5 0x0 0x1f0b0 0x178 0x48c 0x0 0x5 0x0 0x8b0 0x17c 0x490 0x0 0x5 0x0 0x8b0 0xcc 0x3e0 0x948 0x6 0x0 0x1b0b0 0xd0 0x3e4 0x0 0x6 0x0 0x1b0b0 0xa4 0x3b8 0x944 0x4 0x0 0x1b0b0 0xa8 0x3bc 0x0 0x4 0x0 0x1b0b0 0x2b0 0x698 0x0 0x5 0x0 0x1b0b0 0x2b4 0x69c 0x0 0x5 0x0 0x1b0b0 0x2ac 0x694 0x0 0x5 0x0 0x1b0b0 0x2a8 0x690 0x0 0x5 0x0 0x1b0b0 0x194 0x4a8 0x0 0x5 0x0 0x1b0b0 0xe4 0x3f8 0x0 0x5 0x0 0x1b0b0>;
						linux,phandle = <0x19>;
						phandle = <0x19>;
					};
				};
			};

			ldb@020e0008 {
				#address-cells = <0x1>;
				#size-cells = <0x0>;
				gpr = <0x13>;
				status = "okay";
				compatible = "fsl,imx6q-ldb", "fsl,imx53-ldb";
				clocks = <0x2 0x87 0x2 0x88 0x2 0x27 0x2 0x28 0x2 0x29 0x2 0x2a 0x2 0xb8 0x2 0xb9 0x2 0xd1 0x2 0xd2 0x2 0xd3 0x2 0xd4>;
				clock-names = "ldb_di0", "ldb_di1", "di0_sel", "di1_sel", "di2_sel", "di3_sel", "ldb_di0_div_3_5", "ldb_di1_div_3_5", "ldb_di0_div_7", "ldb_di1_div_7", "ldb_di0_div_sel", "ldb_di1_div_sel";

				lvds-channel@0 {
					reg = <0x0>;
					status = "okay";
					crtc = "ipu2-di0";
					vddldb-supply = <0x1a>;
					fsl,data-mapping = "spwg";
					fsl,data-width = <0x18>;
					primary;

					display-timings {
						native-mode = <0x1b>;

						G084SN05V9 {
							clock-frequency = <0x25f4cc0>;
							hactive = <0x320>;
							vactive = <0x258>;
							hback-porch = <0x80>;
							hfront-porch = <0x80>;
							vback-porch = <0xe>;
							vfront-porch = <0xe>;
							hsync-len = <0x1>;
							vsync-len = <0x1>;
							linux,phandle = <0x1b>;
							phandle = <0x1b>;
						};
					};
				};

				lvds-channel@1 {
					reg = <0x1>;
					status = "disabled";
					crtc = "ipu2-di1";
				};
			};

			dcic@020e4000 {
				compatible = "fsl,imx6q-dcic";
				reg = <0x20e4000 0x4000>;
				interrupts = <0x0 0x7c 0x4>;
				clocks = <0x2 0xd6 0x2 0xd6>;
				clock-names = "dcic", "disp-axi";
				gpr = <0x13>;
				status = "okay";
				dcic_id = <0x0>;
				dcic_mux = "dcic-hdmi";
			};

			dcic@020e8000 {
				compatible = "fsl,imx6q-dcic";
				reg = <0x20e8000 0x4000>;
				interrupts = <0x0 0x7d 0x4>;
				clocks = <0x2 0xd7 0x2 0xd7>;
				clock-names = "dcic", "disp-axi";
				gpr = <0x13>;
				status = "disabled";
			};

			sdma@020ec000 {
				compatible = "fsl,imx6q-sdma", "fsl,imx35-sdma";
				reg = <0x20ec000 0x4000>;
				interrupts = <0x0 0x2 0x4>;
				clocks = <0x2 0x9b 0x2 0x9b>;
				clock-names = "ipg", "ahb";
				#dma-cells = <0x3>;
				fsl,sdma-ram-script-name = "imx/sdma/sdma-imx6q.bin";
				linux,phandle = <0x7>;
				phandle = <0x7>;
			};
		};

		aips-bus@02100000 {
			compatible = "fsl,aips-bus", "simple-bus";
			#address-cells = <0x1>;
			#size-cells = <0x1>;
			reg = <0x2100000 0x100000>;
			ranges;

			caam@2100000 {
				compatible = "fsl,sec-v4.0";
				#address-cells = <0x1>;
				#size-cells = <0x1>;
				reg = <0x2100000 0x40000>;
				ranges = <0x0 0x2100000 0x40000>;
				interrupt-parent = <0x1>;
				clocks = <0x2 0xf6 0x2 0xf7 0x2 0xf8 0x2 0xc4>;
				clock-names = "caam_mem", "caam_aclk", "caam_ipg", "caam_emi_slow";

				jr0@1000 {
					compatible = "fsl,sec-v4.0-job-ring";
					reg = <0x1000 0x1000>;
					interrupt-parent = <0x1>;
					interrupts = <0x0 0x69 0x4>;
				};

				jr1@2000 {
					compatible = "fsl,sec-v4.0-job-ring";
					reg = <0x2000 0x1000>;
					interrupt-parent = <0x1>;
					interrupts = <0x0 0x6a 0x4>;
				};
			};

			aipstz@0217c000 {
				reg = <0x217c000 0x4000>;
			};

			usb@02184000 {
				compatible = "fsl,imx6q-usb", "fsl,imx27-usb";
				reg = <0x2184000 0x200>;
				interrupts = <0x0 0x2b 0x4>;
				clocks = <0x2 0xa2>;
				fsl,usbphy = <0x1c>;
				fsl,usbmisc = <0x1d 0x0>;
				fsl,anatop = <0x16>;
				status = "okay";
				vbus-supply = <0x1e>;
				pinctrl-names = "default";
				pinctrl-0 = <0x1f>;
				disable-over-current;
			};

			usb@02184200 {
				compatible = "fsl,imx6q-usb", "fsl,imx27-usb";
				reg = <0x2184200 0x200>;
				interrupts = <0x0 0x28 0x4>;
				clocks = <0x2 0xa2>;
				fsl,usbphy = <0x20>;
				fsl,usbmisc = <0x1d 0x1>;
				status = "okay";
				vbus-supply = <0x21>;
				dr_mode = "host";
			};

			usb@02184400 {
				compatible = "fsl,imx6q-usb", "fsl,imx27-usb";
				reg = <0x2184400 0x200>;
				interrupts = <0x0 0x29 0x4>;
				clocks = <0x2 0xa2>;
				fsl,usbmisc = <0x1d 0x2>;
				phy_type = "hsic";
				fsl,usbphy = <0x22>;
				fsl,anatop = <0x16>;
				status = "disabled";
			};

			usb@02184600 {
				compatible = "fsl,imx6q-usb", "fsl,imx27-usb";
				reg = <0x2184600 0x200>;
				interrupts = <0x0 0x2a 0x4>;
				clocks = <0x2 0xa2>;
				fsl,usbmisc = <0x1d 0x3>;
				phy_type = "hsic";
				fsl,usbphy = <0x23>;
				fsl,anatop = <0x16>;
				status = "disabled";
			};

			usbmisc@02184800 {
				#index-cells = <0x1>;
				compatible = "fsl,imx6q-usbmisc";
				reg = <0x2184800 0x200>;
				clocks = <0x2 0xa2>;
				linux,phandle = <0x1d>;
				phandle = <0x1d>;
			};

			ethernet@02188000 {
				compatible = "fsl,imx6q-fec";
				reg = <0x2188000 0x4000>;
				interrupts-extended = <0x1 0x0 0x76 0x4 0x1 0x0 0x77 0x4>;
				clocks = <0x2 0x75 0x2 0x75 0x2 0xbe>;
				clock-names = "ipg", "ahb", "ptp";
				status = "okay";
				pinctrl-0 = <0x24>;
				pinctrl-1 = <0x25>;
				pinctrl-names = "default", "sleep";
				phy-mode = "rgmii";
				max-speed = <0x3e8>;
				phy-supply = <0x26>;
			};

			mlb@0218c000 {
				compatible = "fsl,imx6q-mlb150";
				reg = <0x218c000 0x4000>;
				interrupts = <0x0 0x35 0x4 0x0 0x75 0x4 0x0 0x7e 0x4>;
				clocks = <0x2 0x8b 0x2 0xaf>;
				clock-names = "mlb", "pll8_mlb";
				iram = <0xd>;
				status = "disabled";
			};

			usdhc@02190000 {
				compatible = "fsl,imx6q-usdhc";
				reg = <0x2190000 0x4000>;
				interrupts = <0x0 0x16 0x4>;
				clocks = <0x2 0xa3 0x2 0xa3 0x2 0xa3>;
				clock-names = "ipg", "ahb", "per";
				bus-width = <0x4>;
				status = "disabled";
			};

			usdhc@02194000 {
				compatible = "fsl,imx6q-usdhc";
				reg = <0x2194000 0x4000>;
				interrupts = <0x0 0x17 0x4>;
				clocks = <0x2 0xa4 0x2 0xa4 0x2 0xa4>;
				clock-names = "ipg", "ahb", "per";
				bus-width = <0x4>;
				status = "okay";
				pinctrl-names = "default";
				pinctrl-0 = <0x27>;
				cd-gpios = <0x28 0x4 0x0>;
				keep-power-in-suspend;
				disable-wp;
				no-1-8-v;
			};

			usdhc@02198000 {
				compatible = "fsl,imx6q-usdhc";
				reg = <0x2198000 0x4000>;
				interrupts = <0x0 0x18 0x4>;
				clocks = <0x2 0xa5 0x2 0xa5 0x2 0xa5>;
				clock-names = "ipg", "ahb", "per";
				bus-width = <0x4>;
				status = "okay";
				pinctrl-names = "default";
				pinctrl-0 = <0x29>;
				non-removable;
				keep-power-in-suspend;
				enable-sdio-wakeup;
			};

			usdhc@0219c000 {
				compatible = "fsl,imx6q-usdhc";
				reg = <0x219c000 0x4000>;
				interrupts = <0x0 0x19 0x4>;
				clocks = <0x2 0xa6 0x2 0xa6 0x2 0xa6>;
				clock-names = "ipg", "ahb", "per";
				bus-width = <0x8>;
				status = "okay";
				pinctrl-names = "default";
				pinctrl-0 = <0x2a>;
				disable-wp;
				non-removable;
				keep-power-in-suspend;
			};

			i2c@021a0000 {
				#address-cells = <0x1>;
				#size-cells = <0x0>;
				compatible = "fsl,imx6q-i2c", "fsl,imx21-i2c";
				reg = <0x21a0000 0x4000>;
				interrupts = <0x0 0x24 0x4>;
				clocks = <0x2 0x7d>;
				status = "okay";
				clock-frequency = <0x186a0>;
				pinctrl-names = "default";
				pinctrl-0 = <0x2b>;

				at24@50 {
					compatible = "at,24c32";
					pagesize = <0x20>;
					reg = <0x50>;
				};

				bq40z60@b {
					pinctrl-names = "default";
					pinctrl-0 = <0x2c>;
					compatible = "bq40z60";
					status = "okay";
					reg = <0xb>;
					gpio-ncharger-prsnt = <0x2d 0x7 0x0>;
					gpio-ncharging = <0x2d 0x10 0x0>;
					gpio-batlow = <0x2d 0xf 0x0>;
					interrupt-parent = <0x2d>;
					interrupts = <0x7 0x1 0xf 0x1>;
				};
			};

			i2c@021a4000 {
				#address-cells = <0x1>;
				#size-cells = <0x0>;
				compatible = "fsl,imx6q-i2c", "fsl,imx21-i2c";
				reg = <0x21a4000 0x4000>;
				interrupts = <0x0 0x25 0x4>;
				clocks = <0x2 0x7e>;
				status = "okay";
				clock-frequency = <0x61a80>;
				pinctrl-names = "default";
				pinctrl-0 = <0x2e>;

				edid@50 {
					compatible = "fsl,imx6-hdmi-i2c";
					reg = <0x50>;
				};

				pfuze100@08 {
					compatible = "fsl,pfuze100";
					reg = <0x8>;
					status = "okay";

					regulators {

						sw1ab {
							regulator-min-microvolt = <0x493e0>;
							regulator-max-microvolt = <0x1c9c38>;
							regulator-boot-on;
							regulator-always-on;
							regulator-ramp-delay = <0x186a>;
						};

						sw1c {
							regulator-min-microvolt = <0x493e0>;
							regulator-max-microvolt = <0x1c9c38>;
							regulator-boot-on;
							regulator-always-on;
							regulator-ramp-delay = <0x186a>;
						};

						sw2 {
							regulator-min-microvolt = <0xc3500>;
							regulator-max-microvolt = <0x325aa0>;
							regulator-boot-on;
							regulator-always-on;
						};

						sw3a {
							regulator-min-microvolt = <0x61a80>;
							regulator-max-microvolt = <0x1e22d8>;
							regulator-boot-on;
							regulator-always-on;
						};

						sw3b {
							regulator-min-microvolt = <0x61a80>;
							regulator-max-microvolt = <0x1e22d8>;
							regulator-boot-on;
							regulator-always-on;
						};

						sw4 {
							regulator-min-microvolt = <0xc3500>;
							regulator-max-microvolt = <0x325aa0>;
							regulator-boot-on;
							regulator-always-on;
						};

						swbst {
							regulator-min-microvolt = <0x4c4b40>;
							regulator-max-microvolt = <0x4e9530>;
							regulator-boot-on;
							regulator-always-on;
							linux,phandle = <0x39>;
							phandle = <0x39>;
						};

						vsnvs {
							regulator-min-microvolt = <0xf4240>;
							regulator-max-microvolt = <0x2dc6c0>;
							regulator-boot-on;
							regulator-always-on;
						};

						vrefddr {
							regulator-boot-on;
							regulator-always-on;
						};

						vgen1 {
							regulator-min-microvolt = <0xc3500>;
							regulator-max-microvolt = <0x17a6b0>;
						};

						vgen2 {
							regulator-min-microvolt = <0xc3500>;
							regulator-max-microvolt = <0x17a6b0>;
						};

						vgen3 {
							regulator-min-microvolt = <0x1b7740>;
							regulator-max-microvolt = <0x325aa0>;
						};

						vgen4 {
							regulator-min-microvolt = <0x1b7740>;
							regulator-max-microvolt = <0x325aa0>;
							linux,phandle = <0x2f>;
							phandle = <0x2f>;
						};

						vgen5 {
							regulator-min-microvolt = <0x1b7740>;
							regulator-max-microvolt = <0x325aa0>;
							regulator-boot-on;
							regulator-always-on;
						};

						vgen6 {
							regulator-min-microvolt = <0x1b7740>;
							regulator-max-microvolt = <0x325aa0>;
							regulator-always-on;
							regulator-boot-on;
						};
					};
				};

				ov5640_mipi@3c {
					compatible = "ovti,ov564x_mipi";
					reg = <0x3c>;
					clocks = <0x2 0xc9>;
					clock-names = "csi_mclk";
					AVDD-supply = <0x2f>;
					AFVDD-supply = <0x30>;
					pwn-gpios = <0x2d 0xa 0x0>;
					rst-gpios = <0x6 0x0 0x0>;
					csi_id = <0x1>;
					mclk = <0x16e3600>;
					mclk_source = <0x0>;
				};
			};

			i2c@021a8000 {
				#address-cells = <0x1>;
				#size-cells = <0x0>;
				compatible = "fsl,imx6q-i2c", "fsl,imx21-i2c";
				reg = <0x21a8000 0x4000>;
				interrupts = <0x0 0x26 0x4>;
				clocks = <0x2 0x7f>;
				status = "okay";
				clock-frequency = <0x186a0>;
				pinctrl-names = "default";
				pinctrl-0 = <0x31>;

				tlv320aic3x@18 {
					compatible = "ti,tlv320aic3x";
					status = "okay";
					reg = <0x18>;
					gpio-reset = <0x6 0x2 0x0>;
					ai3x-micbias-vg = <0x2>;
					linux,phandle = <0x41>;
					phandle = <0x41>;
				};

				mag3110@0e {
					compatible = "fsl,mag3110";
					reg = <0xe>;
					position = <0x1>;
					interrupt-parent = <0x2d>;
					interrupts = <0x12 0x1>;
				};

				isl29023@44 {
					compatible = "fsl,isl29023";
					reg = <0x44>;
					rext = <0x1f3>;
					interrupt-parent = <0x2d>;
					interrupts = <0x11 0x2>;
				};

				mma8451@1c {
					compatible = "fsl,mma8451";
					reg = <0x1c>;
					position = <0x1>;
					interrupt-route = <0x1>;
					interrupt-parent = <0x32>;
					interrupts = <0x0 0x8>;
				};

				mpl3115@60 {
					compatible = "fsl,mpl3115";
					reg = <0x60>;
					interrupt-parent = <0x32>;
					interrupts = <0x1 0x2>;
				};

				tps61050@33 {
					compatible = "ti,tps61050";
					reg = <0x33>;
					operating-mode = <0x2>;
				};
			};

			romcp@021ac000 {
				reg = <0x21ac000 0x4000>;
			};

			mmdc0-1@021b0000 {
				compatible = "fsl,imx6q-mmdc-combine";
				reg = <0x21b0000 0x8000>;
			};

			mmdc@021b0000 {
				compatible = "fsl,imx6q-mmdc";
				reg = <0x21b0000 0x4000>;
			};

			mmdc@021b4000 {
				reg = <0x21b4000 0x4000>;
			};

			weim@021b8000 {
				compatible = "fsl,imx6q-weim";
				reg = <0x21b8000 0x4000>;
				interrupts = <0x0 0xe 0x4>;
				clocks = <0x2 0xc4>;
			};

			ocotp-ctrl@021bc000 {
				compatible = "syscon";
				reg = <0x21bc000 0x4000>;
				clocks = <0x2 0x80>;
				linux,phandle = <0x17>;
				phandle = <0x17>;
			};

			ocotp-fuse@021bc000 {
				compatible = "fsl,imx6q-ocotp";
				reg = <0x21bc000 0x4000>;
				clocks = <0x2 0x80>;
			};

			tzasc@021d0000 {
				reg = <0x21d0000 0x4000>;
				interrupts = <0x0 0x6c 0x4>;
			};

			tzasc@021d4000 {
				reg = <0x21d4000 0x4000>;
				interrupts = <0x0 0x6d 0x4>;
			};

			audmux@021d8000 {
				compatible = "fsl,imx6q-audmux", "fsl,imx31-audmux";
				reg = <0x21d8000 0x4000>;
				status = "okay";
				pinctrl-names = "default";
				pinctrl-0 = <0x33>;
			};

			mipi_csi@021dc000 {
				compatible = "fsl,imx6q-mipi-csi2";
				reg = <0x21dc000 0x4000>;
				interrupts = <0x0 0x64 0x4 0x0 0x65 0x4>;
				clocks = <0x2 0x8a 0x2 0x35 0x2 0xd5>;
				clock-names = "dphy_clk", "pixel_clk", "cfg_clk";
				status = "okay";
				ipu_id = <0x0>;
				csi_id = <0x1>;
				v_channel = <0x0>;
				lanes = <0x2>;
			};

			mipi@021e0000 {
				reg = <0x21e0000 0x4000>;
				compatible = "fsl,imx6q-mipi-dsi";
				interrupts = <0x0 0x66 0x4>;
				gpr = <0x13>;
				clocks = <0x2 0x8a 0x2 0xd5>;
				clock-names = "mipi_pllref_clk", "mipi_cfg_clk";
				status = "disabled";
			};

			vdoa@021e4000 {
				compatible = "fsl,imx6q-vdoa";
				reg = <0x21e4000 0x4000>;
				interrupts = <0x0 0x12 0x4>;
				clocks = <0x2 0xca>;
				iram = <0xd>;
			};

			serial@021e8000 {
				compatible = "fsl,imx6q-uart", "fsl,imx21-uart";
				reg = <0x21e8000 0x4000>;
				interrupts = <0x0 0x1b 0x4>;
				clocks = <0x2 0xa0 0x2 0xa1>;
				clock-names = "ipg", "per";
				dmas = <0x7 0x1b 0x4 0x0 0x7 0x1c 0x4 0x0>;
				dma-names = "rx", "tx";
				status = "okay";
				pinctrl-names = "default";
				pinctrl-0 = <0x34>;
				fsl,uart-has-rtscts;
			};

			serial@021ec000 {
				compatible = "fsl,imx6q-uart", "fsl,imx21-uart";
				reg = <0x21ec000 0x4000>;
				interrupts = <0x0 0x1c 0x4>;
				clocks = <0x2 0xa0 0x2 0xa1>;
				clock-names = "ipg", "per";
				dmas = <0x7 0x1d 0x4 0x0 0x7 0x1e 0x4 0x0>;
				dma-names = "rx", "tx";
				status = "okay";
				pinctrl-names = "default";
				pinctrl-0 = <0x35>;
			};

			serial@021f0000 {
				compatible = "fsl,imx6q-uart", "fsl,imx21-uart";
				reg = <0x21f0000 0x4000>;
				interrupts = <0x0 0x1d 0x4>;
				clocks = <0x2 0xa0 0x2 0xa1>;
				clock-names = "ipg", "per";
				dmas = <0x7 0x1f 0x4 0x0 0x7 0x20 0x4 0x0>;
				dma-names = "rx", "tx";
				status = "disabled";
			};

			serial@021f4000 {
				compatible = "fsl,imx6q-uart", "fsl,imx21-uart";
				reg = <0x21f4000 0x4000>;
				interrupts = <0x0 0x1e 0x4>;
				clocks = <0x2 0xa0 0x2 0xa1>;
				clock-names = "ipg", "per";
				dmas = <0x7 0x21 0x4 0x0 0x7 0x22 0x4 0x0>;
				dma-names = "rx", "tx";
				status = "disabled";
			};
		};

		ipu@02400000 {
			compatible = "fsl,imx6q-ipu";
			reg = <0x2400000 0x400000>;
			interrupts = <0x0 0x6 0x4 0x0 0x5 0x4>;
			clocks = <0x2 0x82 0x2 0x83 0x2 0x84 0x2 0x27 0x2 0x28 0x2 0x87 0x2 0x88>;
			clock-names = "bus", "di0", "di1", "di0_sel", "di1_sel", "ldb_di0", "ldb_di1";
			resets = <0xe 0x2>;
			bypass_reset = <0x0>;
		};

		imx_ion {
			compatible = "fsl,mxc-ion";
			fsl,heap-id = <0x0>;
		};

		busfreq {
			compatible = "fsl,imx_busfreq";
			clocks = <0x2 0xab 0x2 0x6 0x2 0xb 0x2 0x68 0x2 0xac 0x2 0x3a 0x2 0x12 0x2 0x3c 0x2 0x14 0x2 0x3>;
			clock-names = "pll2_bus", "pll2_pfd2_396m", "pll2_198m", "arm", "pll3_usb_otg", "periph", "periph_pre", "periph_clk2", "periph_clk2_sel", "osc";
			interrupts = <0x0 0x6b 0x4 0x0 0x70 0x4 0x0 0x71 0x4 0x0 0x72 0x4>;
			interrupt-names = "irq_busfreq_0", "irq_busfreq_1", "irq_busfreq_2", "irq_busfreq_3";
			fsl,max_ddr_freq = <0x1f78a400>;
		};

		gpu@00130000 {
			compatible = "fsl,imx6q-gpu";
			reg = <0x130000 0x4000 0x134000 0x4000 0x2204000 0x4000 0x0 0x0>;
			reg-names = "iobase_3d", "iobase_2d", "iobase_vg", "phys_baseaddr";
			interrupts = <0x0 0x9 0x4 0x0 0xa 0x4 0x0 0xb 0x4>;
			interrupt-names = "irq_3d", "irq_2d", "irq_vg";
			clocks = <0x2 0x1a 0x2 0x8f 0x2 0x1b 0x2 0x79 0x2 0x7a 0x2 0x4a>;
			clock-names = "gpu2d_axi_clk", "openvg_axi_clk", "gpu3d_axi_clk", "gpu2d_clk", "gpu3d_clk", "gpu3d_shader_clk";
			resets = <0xe 0x0 0xe 0x3 0xe 0x3>;
			reset-names = "gpu3d", "gpu2d", "gpuvg";
			power-domains = <0xf 0x1>;
		};

		sram@00900000 {
			compatible = "fsl,lpm-sram";
			reg = <0x900000 0x4000>;
			clocks = <0x2 0x8e>;
		};

		sram@00904000 {
			compatible = "fsl,ddr-lpm-sram";
			reg = <0x904000 0x1000>;
			clocks = <0x2 0x8e>;
		};

		sram@00905000 {
			compatible = "mmio-sram";
			reg = <0x905000 0x3b000>;
			clocks = <0x2 0x8e>;
			linux,phandle = <0xd>;
			phandle = <0xd>;
		};

		sata@02200000 {
			compatible = "fsl,imx6q-ahci";
			reg = <0x2200000 0x4000>;
			interrupts = <0x0 0x27 0x4>;
			clocks = <0x2 0x9a 0x2 0xbb 0x2 0x69>;
			clock-names = "sata", "sata_ref", "ahb";
			status = "disabled";
		};

		ipu@02800000 {
			compatible = "fsl,imx6q-ipu";
			reg = <0x2800000 0x400000>;
			interrupts = <0x0 0x8 0x4 0x0 0x7 0x4>;
			clocks = <0x2 0x85 0x2 0x86 0x2 0x89 0x2 0x29 0x2 0x2a 0x2 0x87 0x2 0x88>;
			clock-names = "bus", "di0", "di1", "di0_sel", "di1_sel", "ldb_di0", "ldb_di1";
			resets = <0xe 0x4>;
			bypass_reset = <0x0>;
		};
	};

	cpus {
		#address-cells = <0x1>;
		#size-cells = <0x0>;

		cpu@0 {
			compatible = "arm,cortex-a9";
			device_type = "cpu";
			reg = <0x0>;
			next-level-cache = <0x36>;
			operating-points = <0x124f80 0x137478 0xf32a0 0x1312d0 0xd0020 0x1312d0 0xc15c0 0x11edd8 0x60ae0 0xee098>;
			fsl,soc-operating-points = <0x124f80 0x137478 0xf32a0 0x1312d0 0xd0020 0x1312d0 0xc15c0 0x11edd8 0x60ae0 0x11edd8>;
			clock-latency = <0xee6c>;
			clocks = <0x2 0x68 0x2 0x6 0x2 0x10 0x2 0x11 0x2 0xaa 0x2 0xee 0x2 0xe7 0x2 0xe0>;
			clock-names = "arm", "pll2_pfd2_396m", "step", "pll1_sw", "pll1_sys", "pll1_bypass", "pll1", "pll1_bypass_src";
			arm-supply = <0x37>;
			pu-supply = <0x10>;
			soc-supply = <0x38>;
		};

		cpu@1 {
			compatible = "arm,cortex-a9";
			device_type = "cpu";
			reg = <0x1>;
			next-level-cache = <0x36>;
		};

		cpu@2 {
			compatible = "arm,cortex-a9";
			device_type = "cpu";
			reg = <0x2>;
			next-level-cache = <0x36>;
		};

		cpu@3 {
			compatible = "arm,cortex-a9";
			device_type = "cpu";
			reg = <0x3>;
			next-level-cache = <0x36>;
		};
	};

	regulators_cpc1001 {
		compatible = "simple-bus";

		usb_otg_vbus {
			compatible = "regulator-fixed";
			regulator-name = "usb_otg_vbus";
			regulator-min-microvolt = <0x4c4b40>;
			regulator-max-microvolt = <0x4c4b40>;
			gpio = <0x9 0x16 0x0>;
			enable-active-high;
			vin-supply = <0x39>;
			linux,phandle = <0x1e>;
			phandle = <0x1e>;
		};

		usb_h1_vbus {
			compatible = "regulator-fixed";
			regulator-name = "usb_h1_vbus";
			regulator-min-microvolt = <0x4c4b40>;
			regulator-max-microvolt = <0x4c4b40>;
			gpio = <0x9 0x1f 0x0>;
			enable-active-high;
			vin-supply = <0x39>;
			linux,phandle = <0x21>;
			phandle = <0x21>;
		};

		phy {
			compatible = "regulator-micrel-phy";
			regulator-name = "phy";
			regulator-min-microvolt = <0x1b7740>;
			regulator-max-microvolt = <0x1b7740>;
			phy-mode-gpios = <0x2d 0x19 0x0 0x2d 0x1b 0x0 0x2d 0x1c 0x0 0x2d 0x1d 0x0>;
			phy-mode-off = <0x7>;
			phy-mode-on = <0xe>;
			phy-reset-gpio = <0x28 0x19 0x1>;
			pinctrl-names = "default", "state-powerdown";
			pinctrl-0 = <0x3a>;
			pinctrl-1 = <0x3b>;
			startup-delay-us = <0x3e8>;
			linux,phandle = <0x26>;
			phandle = <0x26>;
		};

		cfgdone {
			compatible = "regulator-fixed";
			regulator-name = "nCFGDONE";
			regulator-min-microvolt = <0x325aa0>;
			regulator-max-microvolt = <0x325aa0>;
			gpio = <0x28 0x1c 0x0>;
			regulator-boot-on;
			regulator-always-on;
		};
	};

	gpio-keys {
		compatible = "gpio-keys";
		status = "okay";

		power {
			label = "Power Button";
			gpios = <0x28 0x12 0x1>;
			linux,code = <0x74>;
			gpio-key,wakeup;
			debounce-interval = <0x32>;
		};

		back {
			label = "Back Button";
			gpios = <0x3c 0xc 0x1>;
			linux,code = <0x9e>;
			debounce-interval = <0x32>;
		};

		search {
			label = "Search Button";
			gpios = <0x3c 0xb 0x1>;
			linux,code = <0xd9>;
			debounce-interval = <0x32>;
		};

		home {
			label = "Home Button";
			gpios = <0x3c 0xe 0x1>;
			linux,code = <0xac>;
			debounce-interval = <0x32>;
		};

		menu {
			label = "Menu Button";
			gpios = <0x3c 0xd 0x1>;
			linux,code = <0x8b>;
			debounce-interval = <0x32>;
		};

		lid {
			label = "Lid";
			gpios = <0x5 0x15 0x1>;
			linux,input-type = <0x5>;
			linux,code = <0x0>;
			gpio-key,wakeup;
			debounce-interval = <0x64>;
		};

		dock {
			label = "Dock";
			gpios = <0x9 0x14 0x1>;
			linux,input-type = <0x5>;
			linux,code = <0x4>;
			gpio-key,wakeup;
			debounce-interval = <0x64>;
		};
	};

	sound-hdmi {
		compatible = "fsl,imx6q-audio-hdmi", "fsl,imx-audio-hdmi";
		model = "imx-audio-hdmi";
		hdmi-controller = <0x3d>;
	};

	fb@0 {
		compatible = "fsl,mxc_sdc_fb";
		disp_dev = "ldb";
		interface_pix_fmt = "RGB24";
		mode_str = "800x600M@60";
		default_bpp = <0x20>;
		int_clk = <0x0>;
		late_init = <0x1>;
		status = "okay";
	};

	fb@1 {
		compatible = "fsl,mxc_sdc_fb";
		disp_dev = "hdmi";
		interface_pix_fmt = "RGB24";
		mode_str = "1920x1080M@60";
		default_bpp = <0x18>;
		int_clk = <0x0>;
		late_init = <0x0>;
		status = "disabled";
	};

	fb@2 {
		compatible = "fsl,mxc_sdc_fb";
		disp_dev = "lcd";
		interface_pix_fmt = "RGB565";
		mode_str = "CLAA-WVGA";
		default_bpp = <0x10>;
		int_clk = <0x0>;
		late_init = <0x0>;
		status = "disabled";
	};

	fb@3 {
		compatible = "fsl,mxc_sdc_fb";
		disp_dev = "ldb";
		interface_pix_fmt = "RGB666";
		default_bpp = <0x10>;
		int_clk = <0x0>;
		late_init = <0x0>;
		status = "disabled";
	};

	v4l2_cap_0 {
		compatible = "fsl,imx6q-v4l2-capture";
		ipu_id = <0x0>;
		csi_id = <0x0>;
		mclk_source = <0x0>;
		status = "okay";
	};

	v4l2_cap_1 {
		compatible = "fsl,imx6q-v4l2-capture";
		ipu_id = <0x0>;
		csi_id = <0x1>;
		mclk_source = <0x0>;
		status = "okay";
	};

	v4l2_out {
		compatible = "fsl,mxc_v4l2_output";
		status = "okay";
	};

	regulators_onyx08 {
		compatible = "simple-bus";

		vddldb {
			compatible = "regulator-fixed";
			regulator-name = "vddldb";
			regulator-min-microvolt = <0x325aa0>;
			regulator-max-microvolt = <0x325aa0>;
			gpio = <0x6 0x12 0x0>;
			startup-delay-us = <0x7530>;
			enable-active-high;
			linux,phandle = <0x1a>;
			phandle = <0x1a>;
		};

		tspwr {
			compatible = "regulator-fixed";
			regulator-name = "ts-pwr";
			regulator-min-microvolt = <0x4c4b40>;
			regulator-max-microvolt = <0x4c4b40>;
			gpio = <0x3c 0x7 0x0>;
			regulator-boot-on;
			startup-delay-us = <0x7530>;
			enable-active-high;
			status = "okay";
		};

		wifi {
			compatible = "regulator-fixed";
			regulator-name = "wifi";
			regulator-min-microvolt = <0x1b7740>;
			regulator-max-microvolt = <0x1b7740>;
			gpio = <0x5 0x1d 0x0>;
			enable-active-high;
			startup-delay-us = <0xaae60>;
			regulator-boot-on;
			linux,phandle = <0x3e>;
			phandle = <0x3e>;
		};

		cam_dvdd {
			compatible = "regulator-fixed";
			regulator-name = "cam_afvdd";
			regulator-min-microvolt = <0x2ab980>;
			regulator-max-microvolt = <0x2ab980>;
			gpio = <0x2d 0x9 0x0>;
			enable-active-high;
			vin-supply = <0x2f>;
			linux,phandle = <0x30>;
			phandle = <0x30>;
		};
	};

	wl1271@0 {
		compatible = "fastwel,wl1271-pkm01";
		wifi-supply = <0x3e>;
		bt-shutdown-gpio = <0x5 0x1c 0x0>;
		bt-dev-name = "/dev/ttymxc1";
		bt-flow-cntl = <0x1>;
		bt-baud = <0x2dc6c0>;
		interrupt-parent = <0x5>;
		interrupts = <0x1e 0x4>;
		status = "okay";
	};

	leds {
		compatible = "gpio-leds";
		pinctrl-names = "default";
		pinctrl-0 = <0x3f>;

		red {
			label = "onyx08:red:usr";
			gpios = <0x3c 0xf 0x0>;
		};

		green {
			label = "onyx08:green:usr";
			gpios = <0x3c 0x8 0x0>;
		};
	};

	sound {
		compatible = "fsl,imx-audio-tlv320aic3x";
		status = "okay";
		cpu-dai = <0x40>;
		mux-int-port = <0x2>;
		mux-ext-port = <0x3>;
		audio-codec = <0x41>;
		amp-en-gpios = <0x3c 0x6 0x0>;
		model = "tlv320-audio";
		clocks = <0x2 0xc9>;
		clock-names = "audio-mclk";
		audio-mclk-rate = <0x16e3600>;
		audio-mclk-source = <0x0>;
	};

	backlight {
		compatible = "pwm-backlight";
		pwms = <0x42 0x0 0x4c4b40>;
		brightness-levels = <0x0 0x1 0x2 0x3 0x4 0x5 0x6 0x7 0x8 0x9 0xa 0xb 0xc 0xd 0xe 0xf 0x10 0x11 0x12 0x13 0x14 0x15 0x16 0x17 0x18 0x19 0x1a 0x1b 0x1c 0x1d 0x1e 0x1f 0x20 0x21 0x22 0x23 0x24 0x25 0x26 0x27 0x28 0x29 0x2a 0x2b 0x2c 0x2d 0x2e 0x2f 0x30 0x31 0x32 0x33 0x34 0x35 0x36 0x37 0x38 0x39 0x3a 0x3b 0x3c 0x3d 0x3e 0x3f 0x40 0x41 0x42 0x43 0x44 0x45 0x46 0x47 0x48 0x49 0x4a 0x4b 0x4c 0x4d 0x4e 0x4f 0x50 0x51 0x52 0x53 0x54 0x55 0x56 0x57 0x58 0x59 0x5a 0x5b 0x5c 0x5d 0x5e 0x5f 0x60 0x61 0x62 0x63 0x64 0x65 0x66 0x67 0x68 0x69 0x6a 0x6b 0x6c 0x6d 0x6e 0x6f 0x70 0x71 0x72 0x73 0x74 0x75 0x76 0x77 0x78 0x79 0x7a 0x7b 0x7c 0x7d 0x7e 0x7f 0x80 0x81 0x82 0x83 0x84 0x85 0x86 0x87 0x88 0x89 0x8a 0x8b 0x8c 0x8d 0x8e 0x8f 0x90 0x91 0x92 0x93 0x94 0x95 0x96 0x97 0x98 0x99 0x9a 0x9b 0x9c 0x9d 0x9e 0x9f 0xa0 0xa1 0xa2 0xa3 0xa4 0xa5 0xa6 0xa7 0xa8 0xa9 0xaa 0xab 0xac 0xad 0xae 0xaf 0xb0 0xb1 0xb2 0xb3 0xb4 0xb5 0xb6 0xb7 0xb8 0xb9 0xba 0xbb 0xbc 0xbd 0xbe 0xbf 0xc0 0xc1 0xc2 0xc3 0xc4 0xc5 0xc6 0xc7 0xc8 0xc9 0xca 0xcb 0xcc 0xcd 0xce 0xcf 0xd0 0xd1 0xd2 0xd3 0xd4 0xd5 0xd6 0xd7 0xd8 0xd9 0xda 0xdb 0xdc 0xdd 0xde 0xdf 0xe0 0xe1 0xe2 0xe3 0xe4 0xe5 0xe6 0xe7 0xe8 0xe9 0xea 0xeb 0xec 0xed 0xee 0xef 0xf0 0xf1 0xf2 0xf3 0xf4 0xf5 0xf6 0xf7 0xf8 0xf9 0xfa 0xfb 0xfc 0xfd 0xfe 0xff>;
		default-brightness-level = <0x7f>;
		power-on-delay-ms = <0xb4>;
	};

	key-backlight {
		compatible = "pwm-backlight";
		pwms = <0x43 0x0 0x4c4b40>;
		brightness-levels = <0x0 0x2 0x4 0x8 0x10 0x20 0x30 0x40 0x60 0x80 0xc0 0xff>;
		default-brightness-level = <0x1>;
	};

	ramoops_device {
		compatible = "fsl,mxc_ramoops";
		record_size = <0x80000>;
		console_size = <0x40000>;
		ftrace_size = <0x40000>;
		dump_oops = <0x1>;
		status = "okay";
	};
};
